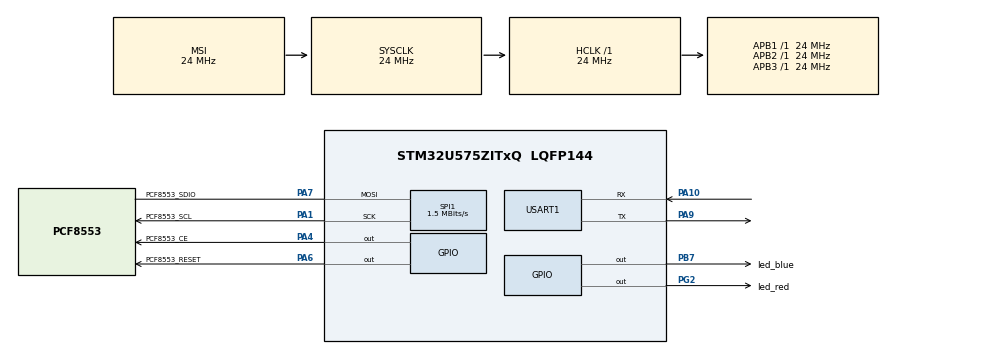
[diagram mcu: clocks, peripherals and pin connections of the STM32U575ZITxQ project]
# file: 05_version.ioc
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CORTEX_M33_NS.userName=CORTEX_M33
Mcu.Family=STM32U5
Mcu.Name=STM32U575ZITxQ
Mcu.Package=LQFP144
NVIC.PriorityGroup=NVIC_PRIORITYGROUP_4
NVIC.TIM6_IRQn=true\:15\:0\:false\:false\:true\:false\:true\:true
NVIC.TimeBase=TIM6_IRQn
NVIC.TimeBaseIP=TIM6
PA1.GPIO_Label=PCF8553_SCL
PA1.Mode=Simplex_Bidirectional_Master
PA1.Signal=SPI1_SCK
PA10.Mode=Asynchronous
PA10.Signal=USART1_RX
PA4.GPIO_Label=PCF8553_CE
PA4.Signal=GPIO_Output
PA6.GPIO_Label=PCF8553_RESET
PA6.Signal=GPIO_Output
PA7.GPIO_Label=PCF8553_SDIO
PA7.Mode=Simplex_Bidirectional_Master
PA7.Signal=SPI1_MOSI
PA9.Mode=Asynchronous
PA9.Signal=USART1_TX
PB7.GPIO_Label=led_blue
PB7.Signal=GPIO_Output
PC14-OSC32_IN\ (PC14).Mode=LSE-External-Oscillator
PC14-OSC32_IN\ (PC14).Signal=RCC_OSC32_IN
PC15-OSC32_OUT\ (PC15).Mode=LSE-External-Oscillator
PC15-OSC32_OUT\ (PC15).Signal=RCC_OSC32_OUT
PG2.GPIO_Label=led_red
PG2.Signal=GPIO_Output
PWR.PowerMode=PWR_SMPS_SUPPLY
ProjectManager.HeapSize=0x200
ProjectManager.StackSize=0x400
ProjectManager.TargetToolchain=STM32CubeIDE
RCC.ADCFreq_Value=16000000
RCC.AHBFreq_Value=24000000
RCC.APB1Freq_Value=24000000
RCC.APB1TimFreq_Value=24000000
RCC.APB2Freq_Value=24000000
RCC.APB2TimFreq_Value=24000000
RCC.APB3Freq_Value=24000000
RCC.CortexFreq_Value=24000000
RCC.EPOD_VALUE=24000000
RCC.HCLKFreq_Value=24000000
RCC.HSE_VALUE=16000000
RCC.HSI48_VALUE=48000000
RCC.HSI_VALUE=16000000
RCC.LSIDIV_VALUE=32000
RCC.MSIClockRange=RCC_MSIRANGE_1
RCC.MSI_VALUE=24000000
RCC.SYSCLKFreq_VALUE=24000000
RCC.USART1CLockSelectionVirtual=RCC_USART1CLKSOURCE_SYSCLK
RCC.USBFreq_Value=48000000
RCC.VCOOutputFreq_Value=3096000000
SPI1.BaudRatePrescaler=SPI_BAUDRATEPRESCALER_16
SPI1.CalculateBaudRate=1.5 MBits/s
SPI1.DataSize=SPI_DATASIZE_8BIT
SPI1.Direction=SPI_DIRECTION_1LINE
SPI1.Mode=SPI_MODE_MASTER
SPI1.NSSPMode=SPI_NSS_PULSE_DISABLE
SPI1.VirtualType=VM_MASTER
USART1.VirtualMode-Asynchronous=VM_ASYNC
VP_ICACHE_VS_ICACHE.Mode=DirectMappedCache
VP_PWR_VS_DBSignals.Mode=DisableDeadBatterySignals
VP_PWR_VS_LPOM.Mode=PowerOptimisation
VP_SYS_VS_tim6.Mode=TIM6
board=custom

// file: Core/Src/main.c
/* USER CODE BEGIN Header */
/**
  ******************************************************************************
  * @file           : main.c
  * @brief          : Main program body
  ******************************************************************************
  * @attention
  *
  * Copyright (c) 2023 STMicroelectronics.
  * All rights reserved.
  *
  * This software is licensed under terms that can be found in the LICENSE file
  * in the root directory of this software component.
  * If no LICENSE file comes with this software, it is provided AS-IS.
  *
  ******************************************************************************
  */
/* USER CODE END Header */
#include "main.h"

/* USER CODE BEGIN Includes */
#include "../../lcd_libs/fm_lcd/fm_lcd.h"
#include "../../fm_version/fm_version.h"
/* USER CODE END Includes */

SPI_HandleTypeDef hspi1;

UART_HandleTypeDef huart1;

void SystemClock_Config(void);
static void SystemPower_Config(void);
static void MX_GPIO_Init(void);
static void MX_ICACHE_Init(void);
static void MX_SPI1_Init(void);
static void MX_USART1_UART_Init(void);

int main(void)
{

  /* MCU Configuration--------------------------------------------------------*/

  /* Reset of all peripherals, Initializes the Flash interface and the Systick. */
  HAL_Init();

  /* Configure the system clock */
  SystemClock_Config();

  /* Configure the System Power */
  SystemPower_Config();

  /* Initialize all configured peripherals */
  MX_GPIO_Init();
  MX_ICACHE_Init();
  MX_SPI1_Init();
  MX_USART1_UART_Init();
  /* USER CODE BEGIN 2 */

  fm_lcd_init();
  fm_lcd_clear();

  const int version_str_lgth = 20;
  char version_str[version_str_lgth];

  /* USER CODE END 2 */

  /* Infinite loop */
  /* USER CODE BEGIN WHILE */
  while (1)
  {
    fm_version_get(version_str, version_str_lgth);

    fm_lcd_puts_rows(version_str, LOW_ROW);
    fm_lcd_puts_unit_volume("VE");
    fm_lcd_refresh();

    HAL_GPIO_TogglePin(led_blue_GPIO_Port, led_blue_Pin);

    HAL_Delay(1000);

    /* USER CODE END WHILE */

  }
}

void SystemClock_Config(void)
{
  RCC_OscInitTypeDef RCC_OscInitStruct = {0};
  RCC_ClkInitTypeDef RCC_ClkInitStruct = {0};

  /** Configure the main internal regulator output voltage
  */
  if (HAL_PWREx_ControlVoltageScaling(PWR_REGULATOR_VOLTAGE_SCALE4) != HAL_OK)
  {
    Error_Handler();
  }

  /** Initializes the CPU, AHB and APB buses clocks
  */
  RCC_OscInitStruct.OscillatorType = RCC_OSCILLATORTYPE_MSI;
  RCC_OscInitStruct.MSIState = RCC_MSI_ON;
  RCC_OscInitStruct.MSICalibrationValue = RCC_MSICALIBRATION_DEFAULT;
  RCC_OscInitStruct.MSIClockRange = RCC_MSIRANGE_1;
  RCC_OscInitStruct.PLL.PLLState = RCC_PLL_NONE;
  if (HAL_RCC_OscConfig(&RCC_OscInitStruct) != HAL_OK)
  {
    Error_Handler();
  }

  /** Initializes the CPU, AHB and APB buses clocks
  */
  RCC_ClkInitStruct.ClockType = RCC_CLOCKTYPE_HCLK|RCC_CLOCKTYPE_SYSCLK
                              |RCC_CLOCKTYPE_PCLK1|RCC_CLOCKTYPE_PCLK2
                              |RCC_CLOCKTYPE_PCLK3;
  RCC_ClkInitStruct.SYSCLKSource = RCC_SYSCLKSOURCE_MSI;
  RCC_ClkInitStruct.AHBCLKDivider = RCC_SYSCLK_DIV1;
  RCC_ClkInitStruct.APB1CLKDivider = RCC_HCLK_DIV1;
  RCC_ClkInitStruct.APB2CLKDivider = RCC_HCLK_DIV1;
  RCC_ClkInitStruct.APB3CLKDivider = RCC_HCLK_DIV1;

  if (HAL_RCC_ClockConfig(&RCC_ClkInitStruct, FLASH_LATENCY_1) != HAL_OK)
  {
    Error_Handler();
  }
}

/**
  * @brief Power Configuration
  * @retval None
  */
static void SystemPower_Config(void)
{
  HAL_PWREx_EnableVddIO2();

  /*
   * Disable the internal Pull-Up in Dead Battery pins of UCPD peripheral
   */
  HAL_PWREx_DisableUCPDDeadBattery();

  /*
   * Switch to SMPS regulator instead of LDO
   */
  if (HAL_PWREx_ConfigSupply(PWR_SMPS_SUPPLY) != HAL_OK)
  {
    Error_Handler();
  }
}

static void MX_ICACHE_Init(void)
{

  /** Enable instruction cache in 1-way (direct mapped cache)
  */
  if (HAL_ICACHE_ConfigAssociativityMode(ICACHE_1WAY) != HAL_OK)
  {
    Error_Handler();
  }
  if (HAL_ICACHE_Enable() != HAL_OK)
  {
    Error_Handler();
  }

}

static void MX_SPI1_Init(void)
{

  SPI_AutonomousModeConfTypeDef HAL_SPI_AutonomousMode_Cfg_Struct = {0};

  /* SPI1 parameter configuration*/
  hspi1.Instance = SPI1;
  hspi1.Init.Mode = SPI_MODE_MASTER;
  hspi1.Init.Direction = SPI_DIRECTION_1LINE;
  hspi1.Init.DataSize = SPI_DATASIZE_8BIT;
  hspi1.Init.CLKPolarity = SPI_POLARITY_LOW;
  hspi1.Init.CLKPhase = SPI_PHASE_1EDGE;
  hspi1.Init.NSS = SPI_NSS_SOFT;
  hspi1.Init.BaudRatePrescaler = SPI_BAUDRATEPRESCALER_16;
  hspi1.Init.FirstBit = SPI_FIRSTBIT_MSB;
  hspi1.Init.TIMode = SPI_TIMODE_DISABLE;
  hspi1.Init.CRCCalculation = SPI_CRCCALCULATION_DISABLE;
  hspi1.Init.CRCPolynomial = 0x7;
  hspi1.Init.NSSPMode = SPI_NSS_PULSE_DISABLE;
  hspi1.Init.NSSPolarity = SPI_NSS_POLARITY_LOW;
  hspi1.Init.FifoThreshold = SPI_FIFO_THRESHOLD_01DATA;
  hspi1.Init.MasterSSIdleness = SPI_MASTER_SS_IDLENESS_00CYCLE;
  hspi1.Init.MasterInterDataIdleness = SPI_MASTER_INTERDATA_IDLENESS_00CYCLE;
  hspi1.Init.MasterReceiverAutoSusp = SPI_MASTER_RX_AUTOSUSP_DISABLE;
  hspi1.Init.MasterKeepIOState = SPI_MASTER_KEEP_IO_STATE_DISABLE;
  hspi1.Init.IOSwap = SPI_IO_SWAP_DISABLE;
  hspi1.Init.ReadyMasterManagement = SPI_RDY_MASTER_MANAGEMENT_INTERNALLY;
  hspi1.Init.ReadyPolarity = SPI_RDY_POLARITY_HIGH;
  if (HAL_SPI_Init(&hspi1) != HAL_OK)
  {
    Error_Handler();
  }
  HAL_SPI_AutonomousMode_Cfg_Struct.TriggerState = SPI_AUTO_MODE_DISABLE;
  HAL_SPI_AutonomousMode_Cfg_Struct.TriggerSelection = SPI_GRP1_GPDMA_CH0_TCF_TRG;
  HAL_SPI_AutonomousMode_Cfg_Struct.TriggerPolarity = SPI_TRIG_POLARITY_RISING;
  if (HAL_SPIEx_SetConfigAutonomousMode(&hspi1, &HAL_SPI_AutonomousMode_Cfg_Struct) != HAL_OK)
  {
    Error_Handler();
  }

}

static void MX_USART1_UART_Init(void)
{

  huart1.Instance = USART1;
  huart1.Init.BaudRate = 115200;
  huart1.Init.WordLength = UART_WORDLENGTH_8B;
  huart1.Init.StopBits = UART_STOPBITS_1;
  huart1.Init.Parity = UART_PARITY_NONE;
  huart1.Init.Mode = UART_MODE_TX_RX;
  huart1.Init.HwFlowCtl = UART_HWCONTROL_NONE;
  huart1.Init.OverSampling = UART_OVERSAMPLING_16;
  huart1.Init.OneBitSampling = UART_ONE_BIT_SAMPLE_DISABLE;
  huart1.Init.ClockPrescaler = UART_PRESCALER_DIV1;
  huart1.AdvancedInit.AdvFeatureInit = UART_ADVFEATURE_NO_INIT;
  if (HAL_UART_Init(&huart1) != HAL_OK)
  {
    Error_Handler();
  }
  if (HAL_UARTEx_SetTxFifoThreshold(&huart1, UART_TXFIFO_THRESHOLD_1_8) != HAL_OK)
  {
    Error_Handler();
  }
  if (HAL_UARTEx_SetRxFifoThreshold(&huart1, UART_RXFIFO_THRESHOLD_1_8) != HAL_OK)
  {
    Error_Handler();
  }
  if (HAL_UARTEx_DisableFifoMode(&huart1) != HAL_OK)
  {
    Error_Handler();
  }

}

static void MX_GPIO_Init(void)
{
  GPIO_InitTypeDef GPIO_InitStruct = {0};

  /* GPIO Ports Clock Enable */
  __HAL_RCC_GPIOC_CLK_ENABLE();
  __HAL_RCC_GPIOA_CLK_ENABLE();
  __HAL_RCC_GPIOG_CLK_ENABLE();
  __HAL_RCC_GPIOB_CLK_ENABLE();

  /*Configure GPIO pin Output Level */
  HAL_GPIO_WritePin(GPIOA, PCF8553_CE_Pin|PCF8553_RESET_Pin, GPIO_PIN_RESET);

  /*Configure GPIO pin Output Level */
  HAL_GPIO_WritePin(led_red_GPIO_Port, led_red_Pin, GPIO_PIN_RESET);

  /*Configure GPIO pin Output Level */
  HAL_GPIO_WritePin(led_blue_GPIO_Port, led_blue_Pin, GPIO_PIN_RESET);

  /*Configure GPIO pins : PCF8553_CE_Pin PCF8553_RESET_Pin */
  GPIO_InitStruct.Pin = PCF8553_CE_Pin|PCF8553_RESET_Pin;
  GPIO_InitStruct.Mode = GPIO_MODE_OUTPUT_PP;
  GPIO_InitStruct.Pull = GPIO_NOPULL;
  GPIO_InitStruct.Speed = GPIO_SPEED_FREQ_LOW;
  HAL_GPIO_Init(GPIOA, &GPIO_InitStruct);

  /*Configure GPIO pin : led_red_Pin */
  GPIO_InitStruct.Pin = led_red_Pin;
  GPIO_InitStruct.Mode = GPIO_MODE_OUTPUT_PP;
  GPIO_InitStruct.Pull = GPIO_NOPULL;
  GPIO_InitStruct.Speed = GPIO_SPEED_FREQ_LOW;
  HAL_GPIO_Init(led_red_GPIO_Port, &GPIO_InitStruct);

  /*Configure GPIO pin : led_blue_Pin */
  GPIO_InitStruct.Pin = led_blue_Pin;
  GPIO_InitStruct.Mode = GPIO_MODE_OUTPUT_PP;
  GPIO_InitStruct.Pull = GPIO_NOPULL;
  GPIO_InitStruct.Speed = GPIO_SPEED_FREQ_LOW;
  HAL_GPIO_Init(led_blue_GPIO_Port, &GPIO_InitStruct);

}

void HAL_TIM_PeriodElapsedCallback(TIM_HandleTypeDef *htim)
{
  if (htim->Instance == TIM6) {
    HAL_IncTick();
  }
}

void Error_Handler(void)
{
  __disable_irq();
  while (1)
  {
  }
}
